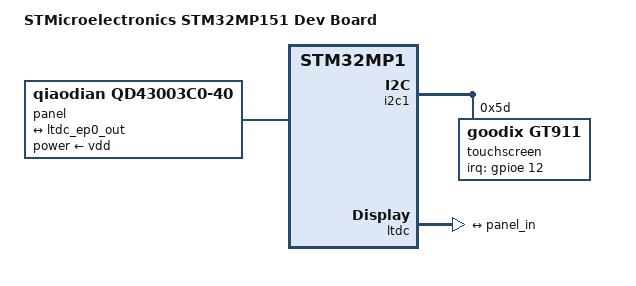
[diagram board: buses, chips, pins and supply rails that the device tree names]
// SPDX-License-Identifier: (GPL-2.0+ OR BSD-3-Clause)
/*
 * Copyright (C) STMicroelectronics 2019 - All Rights Reserved
 * Author: Alexandre Torgue <alexandre.torgue@st.com> for STMicroelectronics.
 */

/dts-v1/;

#include "stm32mp151.dtsi"
#include "stm32mp15xc.dtsi"
#include "stm32mp15-pinctrl.dtsi"
#include "stm32mp15xxac-pinctrl.dtsi"
#include "stm32mp151_dev_board.dtsi"

/ {
	model = "STMicroelectronics STM32MP151 Dev Board";
	compatible = "st,stm32mp151", "st,stm32mp1";

	aliases {
		serial0 = &uart4;
		serial1 = &usart3;
		serial2 = &uart7;
		serial3 = &usart2;
	};

	chosen {
		stdout-path = "serial0:115200n8";
	};

	panel {
		status = "okay";
		compatible = "qiaodian,qd43003c0-40", "simple-panel";
		power-supply = <&vdd>;
		ports {
			#address-cells = <1>;
			#size-cells = <0>;

			port@0 {
				reg = <0>;
				panel_in: endpoint {
					remote-endpoint = <&ltdc_ep0_out>;
				};
			};
		};
	};
};

&i2c1 {
	touchscreen@38 {
		compatible = "goodix,gt911";
		reg = <0x5d>; //0x5d or 0x14
		interrupts = <12 2>;
		interrupt-parent = <&gpioe>;
		interrupt-controller;
		touchscreen-size-x = <480>;
		touchscreen-size-y = <272>;
		status = "okay";
	};
};

&ltdc {
	status = "okay";
	pinctrl-names = "default", "sleep";
	pinctrl-0 = <&ltdc_pins_mx>;
	pinctrl-1 = <&ltdc_sleep_pins_mx>;

	port {
		ltdc_ep0_out: endpoint@0 {
			reg = <0>;
			remote-endpoint = <&panel_in>;
		};
	};
};
